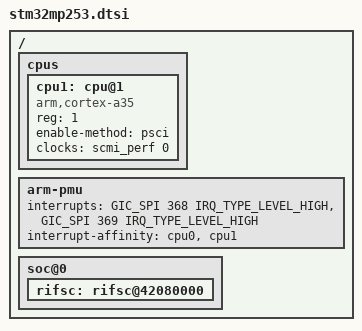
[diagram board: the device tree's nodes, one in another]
// SPDX-License-Identifier: (GPL-2.0-or-later OR BSD-3-Clause)
/*
 * Copyright (C) STMicroelectronics 2023 - All Rights Reserved
 * Author: Alexandre Torgue <alexandre.torgue@foss.st.com> for STMicroelectronics.
 */
#include "stm32mp251.dtsi"

/ {
	cpus {
		cpu1: cpu@1 {
			compatible = "arm,cortex-a35";
			device_type = "cpu";
			reg = <1>;
			enable-method = "psci";
			clocks = <&scmi_perf 0>;
			clock-names = "cpu";
		};
	};

	arm-pmu {
		interrupts = <GIC_SPI 368 IRQ_TYPE_LEVEL_HIGH>,
			     <GIC_SPI 369 IRQ_TYPE_LEVEL_HIGH>;
		interrupt-affinity = <&cpu0>, <&cpu1>;
	};

	soc@0 {
		rifsc: rifsc@42080000 {
		};
	};
};
